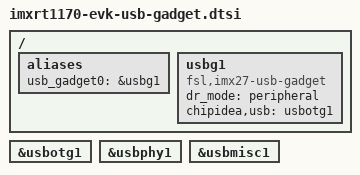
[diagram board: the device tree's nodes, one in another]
// SPDX-License-Identifier: GPL-2.0+
/*
 * USB OTG1 in device mode
 */

/ {
	aliases {
		usb_gadget0 = &usbg1;
	};

	usbg1: usbg1 {
		compatible = "fsl,imx27-usb-gadget";
		dr_mode = "peripheral";
		chipidea,usb = <&usbotg1>;
		status = "okay";
		bootph-pre-ram;
	};
};

&usbotg1 {
	bootph-pre-ram;
};

&usbphy1 {
	bootph-pre-ram;
};

&usbmisc1 {
	bootph-pre-ram;
};
